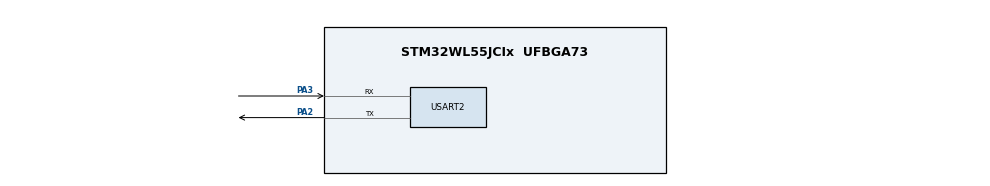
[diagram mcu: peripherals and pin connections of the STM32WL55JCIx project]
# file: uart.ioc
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Mcu.Family=STM32WL
Mcu.Name=STM32WL55JCIx
Mcu.Package=UFBGA73
NVIC.PriorityGroup=NVIC_PRIORITYGROUP_4
PA2.Mode=Asynchronous
PA2.Signal=USART2_TX
PA3.Mode=Asynchronous
PA3.Signal=USART2_RX
ProjectManager.HeapSize=0x200
ProjectManager.StackSize=0x400
ProjectManager.TargetToolchain=MDK-ARM V5.37
RCC.HSE_VALUE=8000000
RCC.HSI_VALUE=16000000
RCC.LSE_VALUE=32768
RCC.VCOOutputFreq_Value=32000000
USART2.VirtualMode-Asynchronous=VM_ASYNC
board=custom

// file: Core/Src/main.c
/* USER CODE BEGIN Header */
/**
  ******************************************************************************
  * @file           : main.c
  * @brief          : Main program body
  ******************************************************************************
  * @attention
  *
  * Copyright (c) 2023 STMicroelectronics.
  * All rights reserved.
  *
  * This software is licensed under terms that can be found in the LICENSE file
  * in the root directory of this software component.
  * If no LICENSE file comes with this software, it is provided AS-IS.
  *
  ******************************************************************************
  */
/* USER CODE END Header */
#include "main.h"

UART_HandleTypeDef huart2;

void SystemClock_Config(void);
static void MX_GPIO_Init(void);
static void MX_USART2_UART_Init(void);

int main(void)
{
  /* USER CODE BEGIN 1 */
	uint8_t data[] = "Hello WillowBee World";
  /* USER CODE END 1 */

  /* MCU Configuration--------------------------------------------------------*/

  /* Reset of all peripherals, Initializes the Flash interface and the Systick. */
  HAL_Init();

  /* Configure the system clock */
  SystemClock_Config();

  /* Initialize all configured peripherals */
  MX_GPIO_Init();
  MX_USART2_UART_Init();
  /* Infinite loop */
  while (1)
  {
		HAL_UART_Transmit(&huart2, data, sizeof(data),0xFFFF);
		HAL_Delay(500);
  }
}

void SystemClock_Config(void)
{
  RCC_OscInitTypeDef RCC_OscInitStruct = {0};
  RCC_ClkInitTypeDef RCC_ClkInitStruct = {0};

  /** Configure the main internal regulator output voltage
  */
  __HAL_PWR_VOLTAGESCALING_CONFIG(PWR_REGULATOR_VOLTAGE_SCALE2);

  /** Initializes the CPU, AHB and APB buses clocks
  */
  RCC_OscInitStruct.OscillatorType = RCC_OSCILLATORTYPE_MSI;
  RCC_OscInitStruct.MSIState = RCC_MSI_ON;
  RCC_OscInitStruct.MSICalibrationValue = RCC_MSICALIBRATION_DEFAULT;
  RCC_OscInitStruct.MSIClockRange = RCC_MSIRANGE_6;
  RCC_OscInitStruct.PLL.PLLState = RCC_PLL_NONE;
  if (HAL_RCC_OscConfig(&RCC_OscInitStruct) != HAL_OK)
  {
    Error_Handler();
  }

  /** Configure the SYSCLKSource, HCLK, PCLK1 and PCLK2 clocks dividers
  */
  RCC_ClkInitStruct.ClockType = RCC_CLOCKTYPE_HCLK3|RCC_CLOCKTYPE_HCLK
                              |RCC_CLOCKTYPE_SYSCLK|RCC_CLOCKTYPE_PCLK1
                              |RCC_CLOCKTYPE_PCLK2;
  RCC_ClkInitStruct.SYSCLKSource = RCC_SYSCLKSOURCE_MSI;
  RCC_ClkInitStruct.AHBCLKDivider = RCC_SYSCLK_DIV1;
  RCC_ClkInitStruct.APB1CLKDivider = RCC_HCLK_DIV1;
  RCC_ClkInitStruct.APB2CLKDivider = RCC_HCLK_DIV1;
  RCC_ClkInitStruct.AHBCLK3Divider = RCC_SYSCLK_DIV1;

  if (HAL_RCC_ClockConfig(&RCC_ClkInitStruct, FLASH_LATENCY_0) != HAL_OK)
  {
    Error_Handler();
  }
}

static void MX_USART2_UART_Init(void)
{

  huart2.Instance = USART2;
  huart2.Init.BaudRate = 115200;
  huart2.Init.WordLength = UART_WORDLENGTH_8B;
  huart2.Init.StopBits = UART_STOPBITS_1;
  huart2.Init.Parity = UART_PARITY_NONE;
  huart2.Init.Mode = UART_MODE_TX_RX;
  huart2.Init.HwFlowCtl = UART_HWCONTROL_NONE;
  huart2.Init.OverSampling = UART_OVERSAMPLING_16;
  huart2.Init.OneBitSampling = UART_ONE_BIT_SAMPLE_DISABLE;
  huart2.Init.ClockPrescaler = UART_PRESCALER_DIV1;
  huart2.AdvancedInit.AdvFeatureInit = UART_ADVFEATURE_NO_INIT;
  if (HAL_UART_Init(&huart2) != HAL_OK)
  {
    Error_Handler();
  }
  if (HAL_UARTEx_SetTxFifoThreshold(&huart2, UART_TXFIFO_THRESHOLD_1_8) != HAL_OK)
  {
    Error_Handler();
  }
  if (HAL_UARTEx_SetRxFifoThreshold(&huart2, UART_RXFIFO_THRESHOLD_1_8) != HAL_OK)
  {
    Error_Handler();
  }
  if (HAL_UARTEx_DisableFifoMode(&huart2) != HAL_OK)
  {
    Error_Handler();
  }

}

static void MX_GPIO_Init(void)
{

  /* GPIO Ports Clock Enable */
  __HAL_RCC_GPIOA_CLK_ENABLE();

}

void Error_Handler(void)
{
  __disable_irq();
  while (1)
  {
  }
}
